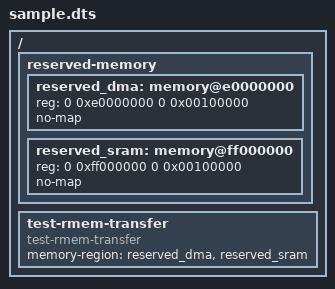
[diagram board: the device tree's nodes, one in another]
// SPDX-License-Identifier: GPL-2.0+ OR MIT
//
// Sample Device Tree Source for test-rmem-transfer
// Author: Kunihiko Hayashi <hayashi.kunihiko@socionext.com>

/{
	reserved-memory {
		#address-cells = <2>;
		#size-cells = <2>;
		ranges;

		reserved_dma: memory@e0000000 {
			reg = <0 0xe0000000 0 0x00100000>;
			no-map;
		};

		reserved_sram: memory@ff000000 {
			reg = <0 0xff000000 0 0x00100000>;
			no-map;
		};
	};

	test-rmem-transfer {
		compatible = "test-rmem-transfer";
		memory-region = <&reserved_dma>, <&reserved_sram>;
	};
};
